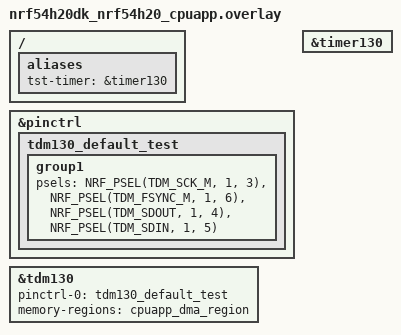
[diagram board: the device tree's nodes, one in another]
/*
 * Copyright (c) 2026 Nordic Semiconductor ASA
 *
 * SPDX-License-Identifier: LicenseRef-Nordic-5-Clause
 */

/ {
	aliases {
		tst-timer = &timer130;
	};
};

&pinctrl {
	tdm130_default_test: tdm130_default_test {
		group1 {
			psels = <NRF_PSEL(TDM_SCK_M, 1, 3)>,
				<NRF_PSEL(TDM_FSYNC_M, 1, 6)>,
				<NRF_PSEL(TDM_SDOUT, 1, 4)>,
				<NRF_PSEL(TDM_SDIN, 1, 5)>;
		};
	};
};

i2s_dut: &tdm130 {
	status = "okay";
	pinctrl-0 = <&tdm130_default_test>;
	pinctrl-names = "default";
	memory-regions = <&cpuapp_dma_region>;
};

&timer130 {
	status = "okay";
};
